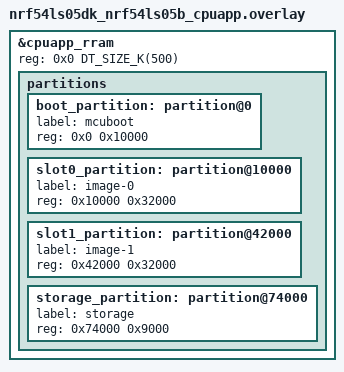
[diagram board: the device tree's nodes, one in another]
/* TODO: Double check partition sizes and ranges */
/delete-node/ &boot_partition;
/delete-node/ &slot0_partition;

&cpuapp_rram {
	reg = <0x0 DT_SIZE_K(500)>;

	partitions {
		boot_partition: partition@0 {
			label = "mcuboot";
			reg = <0x0 0x10000>;
		};

		slot0_partition: partition@10000 {
			label = "image-0";
			reg = <0x10000 0x32000>;
		};

		slot1_partition: partition@42000 {
			label = "image-1";
			reg = < 0x42000 0x32000 >;
		};

		storage_partition: partition@74000 {
			label = "storage";
			reg = < 0x74000 0x9000 >;
		};
	};
};
